# RS1xxxx register map
Vendor: Silicon Lab Inc.; Series: ARMCM4; File version: 1.2
CPU: CM4 r1p0, little endian, MPU, FPU, 6 interrupt priority bits
Registers are 32-bit, read-write, reset 0x0 unless marked. A register's access mark holds for its fields unless they carry their own. Offsets are from the block's base; [hi:lo] are bit positions.

## IID_AES — The AES module provides AES encoding and decoding functionality. It can be used in a microprocessor based environment
Base 0x20480500
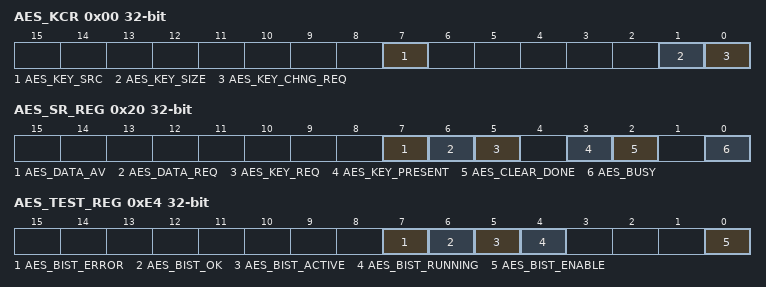
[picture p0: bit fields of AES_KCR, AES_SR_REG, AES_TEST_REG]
0x00 AES_KCR — AES Key Control register
  [7] AES_KEY_SRC — Source of the AES key 0: Interface 1: Register
  [1] AES_KEY_SIZE — Size of the AES key 0: 128-bit 1: 256-bit
  [0] AES_KEY_CHNG_REQ — Programming 1 clears the current key and starts a request a for a new key Auto-reverts to 0 as soon as the request is accepted
0x04 AES_MODE_REG — AES Mode register
  [7:0] AES_MODE — The AES Mode register defines which mode of AES is used.
0x08 AES_ACT_REG — AES Action register
  [1:0] AES_ACTION — The AES Mode register defines which mode of AES is used.
    0=Idle; 1=Encode; 2=Decode; 3=Clear
0x20 AES_SR_REG ro — AES Status register
  [7] AES_DATA_AV — Indicates that data is available
    1=Enable (Indicates that data is available); 0=Disable (none)
  [6] AES_DATA_REQ — Indicates that data must be provided
    1=Enable (Indicates that data must be provided); 0=Disable (none)
  [5] AES_KEY_REQ — Indicates that a key must be provided
    1=Enable (Indicates that a key must be provided); 0=Disable (none)
  [3] AES_KEY_PRESENT — Indicates that the Clear action is finished
    1=Enable (Indicates that a complete key is present); 0=Disable (none)
  [2] AES_CLEAR_DONE — Indicates that the Clear action is finished
    1=Enable (Indicates that the Clear action is finished); 0=Disable (none)
  [0] AES_BUSY — Indicates that the AES core is processing data
    1=Enable (Indicates that the AES core is processing data); 0=Disable (none)
0x40 AES_KEY_REG wo — The AES Key register is used to program a key into the AES module.
  [31:0] AES_KEY — 4 writes of 32 bits make up the 128-bit key for AES, 8 writes make up the 256-bit key
0x44 AES_DIN_REG wo — AES Data In register
  [31:0] AES_DIN — Data for encoding or decoding, 4 writes of 32 bits make up a 128-bit data word
0x48 AES_DOUT_REG ro — AES Data out register
  [31:0] AES_DOUT — Result from encoding or decoding, 4 reads of 32 bits make up a 128-bit data word
0xDC AES_IF_SR_C_REG wo (alternate view of AES_IF_SR_REG) — AES Interface Status Clear register
  [0] IFB_ERROR — Clears the if_error bit
0xE0 AES_IF_SR_REG ro — AES Interface Status register
  [0] IF_ERROR — Indicates that an interface error has occurred
0xE4 AES_TEST_REG — AES Test register
  [7] AES_BIST_ERROR — Indicates that the BIST has failed
  [6] AES_BIST_OK — Indicates that the BIST has passed
  [5] AES_BIST_ACTIVE — Indicates that the BIST is running
  [4] AES_BIST_RUNNING — BIST is in progress or finishing up
  [0] AES_BIST_ENABLE — Isolates the iid_aes module and runs a BIST
0x100 AES_VER_REG ro — AES Version register
  [31:0] AES_VERSION — Version of iid_aes

## IID_QK — The purpose of Quiddikey is to provide secure key storage without storing the key.
Base 0x20480600
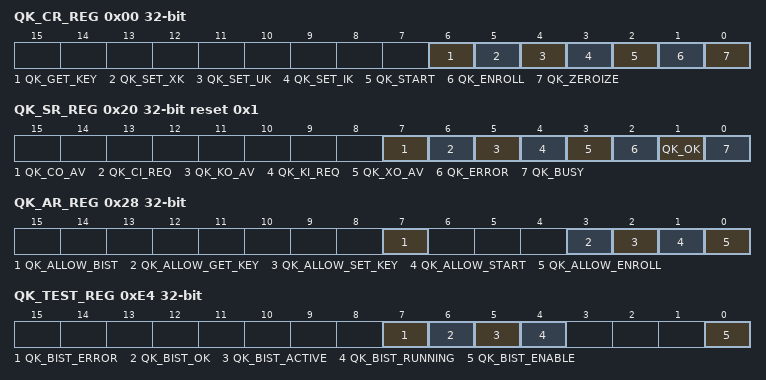
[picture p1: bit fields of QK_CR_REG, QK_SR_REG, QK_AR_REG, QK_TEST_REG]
0x00 QK_CR_REG wo — Quiddikey Control register.The Quiddikey Control register defines which command must be executed next.
  [6] QK_GET_KEY — Begin Get Key operation
  [5] QK_SET_XK — Begin Set External Key operation
  [4] QK_SET_UK — Begin Set User Key operation
  [3] QK_SET_IK — Begin Set Intrinsic Key operation
  [2] QK_START — Begin Start operation
  [1] QK_ENROLL — Begin Enroll operation
  [0] QK_ZEROIZE — Begin Zeroize operation and go to Error state
0x04 QK_KIDX_REG — The Quiddikey Key Index register defines the key index for the next set_key command
  [3:0] QK_KEY_INDEX — Key index for Set Key operations
0x08 QK_KSZ_REG — Quiddikey Key Size register
  [5:0] QK_KEY_SIZE — Key size for Set Key operations
0x0C QK_KT_REG — Quiddikey Key Size register
  [0] QK_KEY_TARGET — Target of reconstructed key
0x20 QK_SR_REG ro reset 0x1 — Quiddikey Status register
  [7] QK_CO_AV — Next part of AC/KC is available
  [6] QK_CI_REQ — Request for next part of AC/KC
  [5] QK_KO_AV — Next part of key is available
  [4] QK_KI_REQ — Request for next part of key
  [3] QK_XO_AV — Next part of XKPD is available
  [2] QK_ERROR — Quiddikey is in the Error state and no operations can be performed
  [1] QK_OK — Last operation was successful
  [0] QK_BUSY — Indicates that operation is in progress
0x28 QK_AR_REG ro — Quiddikey allow register
  [7] QK_ALLOW_BIST — BIST is allowed to be started
  [3] QK_ALLOW_GET_KEY — Get Key operation is allowed
  [2] QK_ALLOW_SET_KEY — Set Key operations are allowed
  [1] QK_ALLOW_START — Start operation is allowed
  [0] QK_ALLOW_ENROLL — Enroll operation is allowed
0x40 QK_KI_REG — Quiddikey Key Input register
  [31:0] QK_KI — Key input data
0x44 QK_CI_REG — Quiddikey Code Input register
  [31:0] QK_CI — AC/KC input data
0x48 QK_CO_REG ro — Quiddikey Code Output register
  [31:0] QK_CO — AC/KC output data
0x4C QK_XO_REG ro — Quiddikey XKPD Output register
  [31:0] QK_XO — XKPD output data
0x60 QK_KO_IDX_REG ro — Quiddikey Key Output Index register
  [3:0] qk_ko_index — Key index for the key that is currently output via the Key Output register
0x64 QK_KO_REG ro — Quiddikey Code Output register
  [31:0] QK_KO — Key output data
0xDC QK_IF_SR_C_REG ro (alternate view of QK_IF_SR_REG) — Quiddikey Interface Status register
  [0] IF_ERROR — Clears the if_error bit
0xE0 QK_IF_SR_REG ro — Quiddikey Interface Status register
  [0] IF_ERROR — Indicates that an interface error has occurred
0xE4 QK_TEST_REG — QK Test register
  [7] QK_BIST_ERROR — Indicates that the BIST has failed
  [6] QK_BIST_OK — Indicates that the BIST has passed
  [5] QK_BIST_ACTIVE — Indicates that the BIST is running
  [4] QK_BIST_RUNNING — BIST is in progress or finishing up
  [0] QK_BIST_ENABLE — Isolates the iid_quiddikey module and runs a BIST
0x100 QK_VER_REG ro — QK Version register
  [31:0] QK_VERSION — Version of iid_qk
